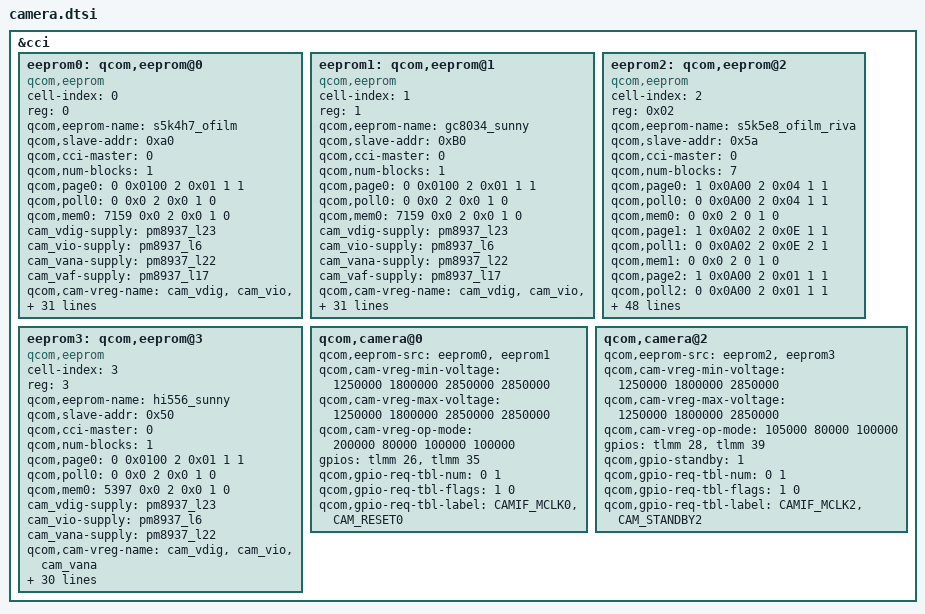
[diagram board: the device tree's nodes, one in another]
/* From stock msm8917-camera-sensor-qrd_S88508.dtsi */
&cci {
	eeprom0: qcom,eeprom@0 {
		cell-index = <0>;
		reg = <0>;
		qcom,eeprom-name = "s5k4h7_ofilm";
		compatible = "qcom,eeprom";
		qcom,slave-addr = <0xa0>;
		qcom,cci-master = <0>;
		qcom,num-blocks = <1>;

		qcom,page0 = <0 0x0100 2 0x01 1 1>;
		qcom,poll0 = <0 0x0 2 0x0 1 0>;
		qcom,mem0 = <7159 0x0 2 0x0 1 0>;

		cam_vdig-supply = <&pm8937_l23>;
		cam_vio-supply = <&pm8937_l6>;
		cam_vana-supply = <&pm8937_l22>;
		cam_vaf-supply = <&pm8937_l17>;
		qcom,cam-vreg-name = "cam_vdig", "cam_vio", "cam_vana",
							"cam_vaf";
		qcom,cam-vreg-min-voltage = <1200000 1800000 2850000 2850000>;
		qcom,cam-vreg-max-voltage = <1200000 1800000 2850000 2850000>;
		qcom,cam-vreg-op-mode = <200000 200000 100000 100000>;
		pinctrl-names = "cam_default", "cam_suspend";
		pinctrl-0 = <&cam_sensor_mclk0_default &cam_sensor_rear_default>;
		pinctrl-1 = <&cam_sensor_mclk0_sleep &cam_sensor_rear_sleep>;
		gpios = <&tlmm 26 0>,
			<&tlmm 35 0>;
		qcom,gpio-reset = <1>;
		qcom,gpio-req-tbl-num = <0 1>;
		qcom,gpio-req-tbl-flags = <1 0>;
		qcom,gpio-req-tbl-label = "CAMIF_MCLK0",
			"CAM_RESET0";

		qcom,cam-power-seq-type =
			"sensor_gpio",
			"sensor_gpio",
			"sensor_vreg",
			"sensor_vreg",
			"sensor_vreg",
			"sensor_gpio",
			"sensor_gpio",
			"sensor_clk";
		qcom,cam-power-seq-val =
			"sensor_gpio_reset",
			"sensor_gpio_standby",
			"cam_vana",
			"cam_vdig",
			"cam_vio",
			"sensor_gpio_reset",
			"sensor_gpio_standby",
			"sensor_cam_mclk";
		qcom,cam-power-seq-cfg-val = <0 0 1 1 1 1 1 24000000>;
		qcom,cam-power-seq-delay = <5 1 1 1 1 10 1 1>;
		status = "ok";
		clocks = <&gcc MCLK0_CLK_SRC>,
				<&gcc GCC_CAMSS_MCLK0_CLK>;
		clock-names = "cam_src_clk", "cam_clk";
		qcom,clock-rates = <24000000 0>;
	};
	eeprom1: qcom,eeprom@1 {
		cell-index = <1>;
		reg = <1>;
		qcom,eeprom-name = "gc8034_sunny";
		compatible = "qcom,eeprom";
		qcom,slave-addr = <0xB0>;
		qcom,cci-master = <0>;
		qcom,num-blocks = <1>;

		qcom,page0 = <0 0x0100 2 0x01 1 1>;
		qcom,poll0 = <0 0x0 2 0x0 1 0>;
		qcom,mem0 = <7159 0x0 2 0x0 1 0>;

		cam_vdig-supply = <&pm8937_l23>;
		cam_vio-supply = <&pm8937_l6>;
		cam_vana-supply = <&pm8937_l22>;
		cam_vaf-supply = <&pm8937_l17>;
		qcom,cam-vreg-name = "cam_vdig", "cam_vio", "cam_vana",
							"cam_vaf";
		qcom,cam-vreg-min-voltage = <1200000 1800000 2850000 2850000>;
		qcom,cam-vreg-max-voltage = <1200000 1800000 2850000 2850000>;
		qcom,cam-vreg-op-mode = <200000 200000 100000 100000>;
		pinctrl-names = "cam_default", "cam_suspend";
		pinctrl-0 = <&cam_sensor_mclk0_default &cam_sensor_rear_default>;
		pinctrl-1 = <&cam_sensor_mclk0_sleep &cam_sensor_rear_sleep>;
		gpios = <&tlmm 26 0>,
			<&tlmm 35 0>;
		qcom,gpio-reset = <1>;
		qcom,gpio-req-tbl-num = <0 1>;
		qcom,gpio-req-tbl-flags = <1 0>;
		qcom,gpio-req-tbl-label = "CAMIF_MCLK0",
			"CAM_RESET0";

		qcom,cam-power-seq-type =
			"sensor_gpio",
			"sensor_gpio",
			"sensor_vreg",
			"sensor_vreg",
			"sensor_vreg",
			"sensor_gpio",
			"sensor_gpio",
			"sensor_clk";
		qcom,cam-power-seq-val =
			"sensor_gpio_reset",
			"sensor_gpio_standby",
			"cam_vana",
			"cam_vdig",
			"cam_vio",
			"sensor_gpio_reset",
			"sensor_gpio_standby",
			"sensor_cam_mclk";
		qcom,cam-power-seq-cfg-val = <0 0 1 1 1 1 1 24000000>;
		qcom,cam-power-seq-delay = <5 1 1 1 1 10 1 1>;
		status = "ok";
		clocks = <&gcc MCLK0_CLK_SRC>,
				<&gcc GCC_CAMSS_MCLK0_CLK>;
		clock-names = "cam_src_clk", "cam_clk";
		qcom,clock-rates = <24000000 0>;
	};
	eeprom2: qcom,eeprom@2 {
		cell-index = <2>;
		reg = <0x02>;
		qcom,eeprom-name = "s5k5e8_ofilm_riva";
		compatible = "qcom,eeprom";
		qcom,slave-addr = <0x5a>;
		qcom,cci-master = <0>;

		qcom,num-blocks = <7>;
		//make initial state
		qcom,page0 = <1 0x0A00 2 0x04 1 1>;
		qcom,poll0 = <0 0x0A00 2 0x04 1 1>;
		qcom,mem0 = <0 0x0 2 0 1 0>;
		//set the PAGE14 of OTP and read data
		qcom,page1 = <1 0x0A02 2 0x0E 1 1>;
		qcom,poll1 = <0 0x0A02 2 0x0E 2 1>;
		qcom,mem1 = <0 0x0 2 0 1 0>;
		//set read mode of NVM controller interface1
		qcom,page2 = <1 0x0A00 2 0x01 1 1>;
		qcom,poll2 = <0 0x0A00 2 0x01 1 1>;
		qcom,mem2 = <64 0x0A04 2 0 1 1>;
		//set the PAGE15 of OTP and read data
		qcom,page3 = <1 0x0A02 2 0x0F 1 1>;
		qcom,poll3 = <0 0x0A02 2 0x0F 2 1>;
		qcom,mem3 = <0 0x0 2 0 1 0>;
		//set read mode of NVM controller interface1
		qcom,page4 = <1 0x0A00 2 0x01 1 1>;
		qcom,poll4 = <0 0x0A00 2 0x01 1 1>;
		qcom,mem4 = <16 0x0A04 2 0 1 1>;
		//make initial state
		qcom,page5 = <1 0x0A00 2 0x04 1 1>;
		qcom,poll5 = <0 0x0A00 2 0x04 1 1>;
		qcom,mem5 = <0 0x0 2 0 1 0>;
		//disable NVM controller
		qcom,page6 = <1 0x0A00 2 0x00 1 1>;
		qcom,poll6 =   <0 0x0A00 2 0x00 1 0>;
		qcom,mem6 = <0 0x0 2 0 1 0>;

		cam_vdig-supply = <&pm8937_l23>;
		cam_vio-supply = <&pm8937_l6>;
		cam_vana-supply = <&pm8937_l22>;
		qcom,cam-vreg-name = "cam_vdig", "cam_vio", "cam_vana";
		qcom,cam-vreg-min-voltage = <1200000 1800000 2850000>;
		qcom,cam-vreg-max-voltage = <1200000 1800000 2850000>;
		qcom,cam-vreg-op-mode = <200000 80000 100000>;
		qcom,gpio-no-mux = <0>;
		pinctrl-names = "cam_default", "cam_suspend";
		pinctrl-0 = <&cam_sensor_mclk2_default
					&cam_sensor_front1_default>;
		pinctrl-1 = <&cam_sensor_mclk2_sleep
					&cam_sensor_front1_sleep>;
		gpios = <&tlmm 28 0>,
			<&tlmm 39 0>;
		qcom,gpio-standby = <1>;
		qcom,gpio-req-tbl-num = <0 1>;
		qcom,gpio-req-tbl-flags = <1 0>;
		qcom,gpio-req-tbl-label = "CAMIF_MCLK2",
					  "CAM_STANDBY2";

		qcom,cam-power-seq-type =
			"sensor_gpio",
			"sensor_gpio",
			"sensor_clk",
			"sensor_vreg",
			"sensor_vreg",
			"sensor_vreg",
			"sensor_gpio",
			"sensor_gpio";
		qcom,cam-power-seq-val =
			"sensor_gpio_reset",
			"sensor_gpio_standby",
			"sensor_cam_mclk",
			"cam_vdig",
			"cam_vana",
			"cam_vio",
			"sensor_gpio_reset",
			"sensor_gpio_standby";
		qcom,cam-power-seq-cfg-val = <0 0 24000000 1 1 1 1 1>;
		qcom,cam-power-seq-delay = <1 5 1 1 1 1 1 1 10>;
		status = "ok";
		clocks = <&gcc MCLK2_CLK_SRC>,
			<&gcc GCC_CAMSS_MCLK2_CLK>;
		clock-names = "cam_src_clk", "cam_clk";
		qcom,clock-rates = <24000000 0>;
	};
	eeprom3: qcom,eeprom@3 {
		cell-index = <3>;
		reg = <3>;
		qcom,eeprom-name = "hi556_sunny";
		compatible = "qcom,eeprom";
		qcom,slave-addr = <0x50>;
		qcom,cci-master = <0>;
		qcom,num-blocks = <1>;

		qcom,page0 = <0 0x0100 2 0x01 1 1>;
		qcom,poll0 = <0 0x0 2 0x0 1 0>;
		qcom,mem0 = <5397 0x0 2 0x0 1 0>;

		cam_vdig-supply = <&pm8937_l23>;
		cam_vio-supply = <&pm8937_l6>;
		cam_vana-supply = <&pm8937_l22>;
		qcom,cam-vreg-name = "cam_vdig", "cam_vio", "cam_vana";
		qcom,cam-vreg-min-voltage = <1200000 1800000 2850000>;
		qcom,cam-vreg-max-voltage = <1200000 1800000 2850000>;
		qcom,cam-vreg-op-mode = <200000 80000 100000>;
		qcom,gpio-no-mux = <0>;
		pinctrl-names = "cam_default", "cam_suspend";
		pinctrl-0 = <&cam_sensor_mclk2_default
					&cam_sensor_front1_default>;
		pinctrl-1 = <&cam_sensor_mclk2_sleep
					&cam_sensor_front1_sleep>;
		gpios = <&tlmm 28 0>,
			<&tlmm 39 0>;
		qcom,gpio-standby = <1>;
		qcom,gpio-req-tbl-num = <0 1>;
		qcom,gpio-req-tbl-flags = <1 0>;
		qcom,gpio-req-tbl-label = "CAMIF_MCLK2",
					  "CAM_STANDBY2";

		qcom,cam-power-seq-type =
			"sensor_gpio",
			"sensor_gpio",
			"sensor_clk",
			"sensor_vreg",
			"sensor_vreg",
			"sensor_vreg",
			"sensor_gpio",
			"sensor_gpio";
		qcom,cam-power-seq-val =
			"sensor_gpio_reset",
			"sensor_gpio_standby",
			"sensor_cam_mclk",
			"cam_vdig",
			"cam_vana",
			"cam_vio",
			"sensor_gpio_reset",
			"sensor_gpio_standby";
		qcom,cam-power-seq-cfg-val = <0 0 24000000 1 1 1 1 1>;
		qcom,cam-power-seq-delay = <1 5 1 1 1 1 1 1 10>;
		status = "ok";
		clocks = <&gcc MCLK2_CLK_SRC>,
			<&gcc GCC_CAMSS_MCLK2_CLK>;
		clock-names = "cam_src_clk", "cam_clk";
		qcom,clock-rates = <24000000 0>;
	};

	qcom,camera@0 {
		qcom,eeprom-src = <&eeprom0 &eeprom1>;
		qcom,cam-vreg-min-voltage = <1250000 1800000 2850000 2850000>;
		qcom,cam-vreg-max-voltage = <1250000 1800000 2850000 2850000>;
		qcom,cam-vreg-op-mode = <200000 80000 100000 100000>;
		gpios = <&tlmm 26 0>,
			<&tlmm 35 0>;
		qcom,gpio-req-tbl-num = <0 1>;
		qcom,gpio-req-tbl-flags = <1 0>;
		qcom,gpio-req-tbl-label = "CAMIF_MCLK0",
			"CAM_RESET0";
	};

	qcom,camera@2 {
		qcom,eeprom-src = <&eeprom2 &eeprom3>;
		qcom,cam-vreg-min-voltage = <1250000 1800000 2850000>;
		qcom,cam-vreg-max-voltage = <1250000 1800000 2850000>;
		qcom,cam-vreg-op-mode = <105000 80000 100000>;
		gpios = <&tlmm 28 0>,
			<&tlmm 39 0>;
		qcom,gpio-standby = <1>;
		qcom,gpio-req-tbl-num = <0 1>;
		qcom,gpio-req-tbl-flags = <1 0>;
		qcom,gpio-req-tbl-label = "CAMIF_MCLK2",
					  "CAM_STANDBY2";
	};
};
